VERSION "Khalil Window Control System 1.0"

NS_ :

BS_:

BU_: MASTER SLAVE

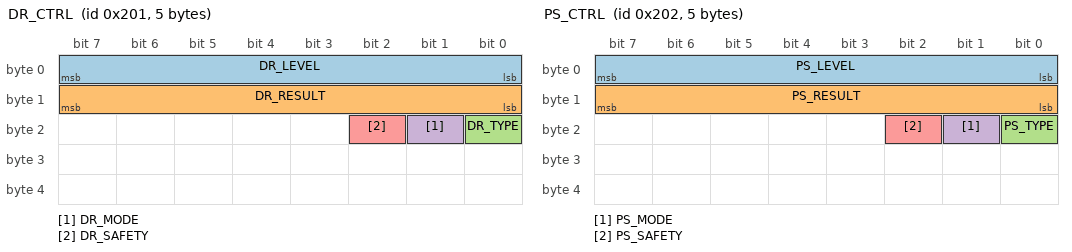
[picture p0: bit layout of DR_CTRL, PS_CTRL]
BO_ 513 DR_CTRL: 5 MASTER
 SG_ DR_LEVEL : 0|8@1+ (1,0) [0|100] "%" SLAVE
 SG_ DR_RESULT : 8|8@1+ (1,0) [0|20] "" SLAVE
 SG_ DR_TYPE : 16|1@1+ (1,0) [0|1] "" SLAVE
 SG_ DR_MODE : 17|1@1+ (1,0) [0|1] "" SLAVE
 SG_ DR_SAFETY : 18|1@1+ (1,0) [0|1] "" SLAVE

BO_ 514 PS_CTRL: 5 MASTER
 SG_ PS_LEVEL : 0|8@1+ (1,0) [0|100] "%" SLAVE
 SG_ PS_RESULT : 8|8@1+ (1,0) [0|20] "" SLAVE
 SG_ PS_TYPE : 16|1@1+ (1,0) [0|1] "" SLAVE
 SG_ PS_MODE : 17|1@1+ (1,0) [0|1] "" SLAVE
 SG_ PS_SAFETY : 18|1@1+ (1,0) [0|1] "" SLAVE

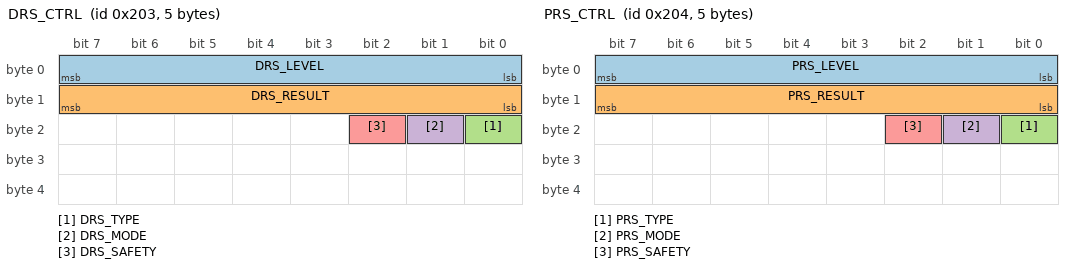
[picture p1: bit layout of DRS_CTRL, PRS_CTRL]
BO_ 515 DRS_CTRL: 5 MASTER
 SG_ DRS_LEVEL : 0|8@1+ (1,0) [0|100] "%" SLAVE
 SG_ DRS_RESULT : 8|8@1+ (1,0) [0|20] "" SLAVE
 SG_ DRS_TYPE : 16|1@1+ (1,0) [0|1] "" SLAVE
 SG_ DRS_MODE : 17|1@1+ (1,0) [0|1] "" SLAVE
 SG_ DRS_SAFETY : 18|1@1+ (1,0) [0|1] "" SLAVE

BO_ 516 PRS_CTRL: 5 MASTER
 SG_ PRS_LEVEL : 0|8@1+ (1,0) [0|100] "%" SLAVE
 SG_ PRS_RESULT : 8|8@1+ (1,0) [0|20] "" SLAVE
 SG_ PRS_TYPE : 16|1@1+ (1,0) [0|1] "" SLAVE
 SG_ PRS_MODE : 17|1@1+ (1,0) [0|1] "" SLAVE
 SG_ PRS_SAFETY : 18|1@1+ (1,0) [0|1] "" SLAVE

VAL_ 513 DR_RESULT 0 "OP" 1 "CL" 2 "OPG" 3 "CLG" 4 "FOP" 5 "OP_D" 6 "CL_D" 7 "OPG_D" 8 "CLG_D" 9 "FOP_D" 10 "OP_AD" 11 "CL_AD" 12 "OPG_AD" 13 "CLG_AD" 14 "FOP_AD" 15 "OP_A" 16 "CL_A" 17 "OPG_A" 18 "CLG_A" 19 "FOP_A" 20 "FAILED";
VAL_ 513 DR_TYPE 0 "AUTO" 1 "MANUAL";
VAL_ 513 DR_MODE 0 "WHONEN" 1 "FAHREN";
VAL_ 513 DR_SAFETY 0 "OFF" 1 "ON";

VAL_ 514 PS_RESULT 0 "OP" 1 "CL" 2 "OPG" 3 "CLG" 4 "FOP" 5 "OP_D" 6 "CL_D" 7 "OPG_D" 8 "CLG_D" 9 "FOP_D" 10 "OP_AD" 11 "CL_AD" 12 "OPG_AD" 13 "CLG_AD" 14 "FOP_AD" 15 "OP_A" 16 "CL_A" 17 "OPG_A" 18 "CLG_A" 19 "FOP_A" 20 "FAILED";
VAL_ 514 PS_TYPE 0 "AUTO" 1 "MANUAL";
VAL_ 514 PS_MODE 0 "WHONEN" 1 "FAHREN";
VAL_ 514 PS_SAFETY 0 "OFF" 1 "ON";

VAL_ 515 DRS_RESULT 0 "OP" 1 "CL" 2 "OPG" 3 "CLG" 4 "FOP" 5 "OP_D" 6 "CL_D" 7 "OPG_D" 8 "CLG_D" 9 "FOP_D" 10 "OP_AD" 11 "CL_AD" 12 "OPG_AD" 13 "CLG_AD" 14 "FOP_AD" 15 "OP_A" 16 "CL_A" 17 "OPG_A" 18 "CLG_A" 19 "FOP_A" 20 "FAILED";
VAL_ 515 DRS_TYPE 0 "AUTO" 1 "MANUAL";
VAL_ 515 DRS_MODE 0 "WHONEN" 1 "FAHREN";
VAL_ 515 DRS_SAFETY 0 "OFF" 1 "ON";

VAL_ 516 PRS_RESULT 0 "OP" 1 "CL" 2 "OPG" 3 "CLG" 4 "FOP" 5 "OP_D" 6 "CL_D" 7 "OPG_D" 8 "CLG_D" 9 "FOP_D" 10 "OP_AD" 11 "CL_AD" 12 "OPG_AD" 13 "CLG_AD" 14 "FOP_AD" 15 "OP_A" 16 "CL_A" 17 "OPG_A" 18 "CLG_A" 19 "FOP_A" 20 "FAILED";
VAL_ 516 PRS_TYPE 0 "AUTO" 1 "MANUAL";
VAL_ 516 PRS_MODE 0 "WHONEN" 1 "FAHREN";
VAL_ 516 PRS_SAFETY 0 "OFF" 1 "ON";
